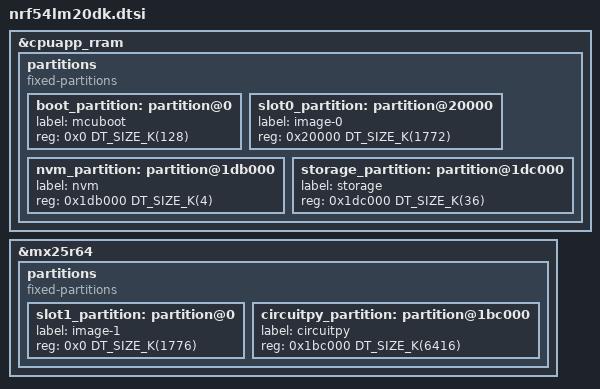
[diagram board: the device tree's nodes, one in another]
&cpuapp_rram {
	partitions {
		compatible = "fixed-partitions";
		#address-cells = <1>;
		#size-cells = <1>;

		boot_partition: partition@0 {
			label = "mcuboot";
			reg = <0x0 DT_SIZE_K(128)>;
		};

		slot0_partition: partition@20000 {
			label = "image-0";
			reg = <0x20000 DT_SIZE_K(1772)>;
		};

		nvm_partition: partition@1db000 {
			label = "nvm";
			reg = <0x1db000 DT_SIZE_K(4)>;
		};

		storage_partition: partition@1dc000 {
			label = "storage";
			reg = <0x1dc000 DT_SIZE_K(36)>;
		};
	};
};

&mx25r64 {
	partitions {
		compatible = "fixed-partitions";
		#address-cells = <1>;
		#size-cells = <1>;

		slot1_partition: partition@0 {
			label = "image-1";
			reg = <0x0 DT_SIZE_K(1776)>;
		};

		circuitpy_partition: partition@1bc000 {
			label = "circuitpy";
			reg = <0x1bc000 DT_SIZE_K(6416)>;
		};
	};
};
